# STM32WBA55 register map
File version: 1.0
CPU: CM33 r0p1, little endian, MPU, FPU, 4 interrupt priority bits
Registers are 32-bit, read-write, reset 0x0 unless marked. A register's access mark holds for its fields unless they carry their own. Offsets are from the block's base; [hi:lo] are bit positions; {n}, {i} and the like mark numbered series; 'fields as' and 'values as' point back to an identical list.

## GPDMA — General purpose direct memory access controller
Base 0x40020000
Same registers: SEC_GPDMA 0x50020000
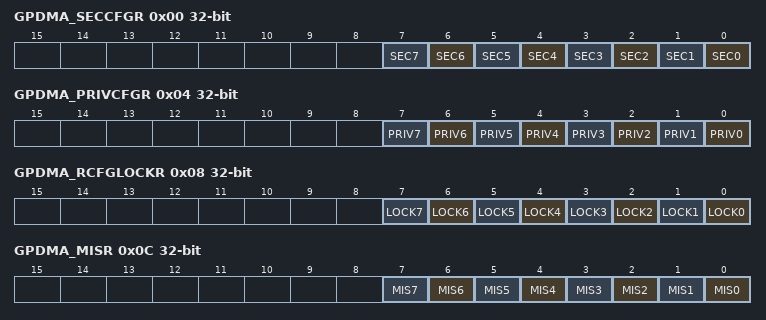
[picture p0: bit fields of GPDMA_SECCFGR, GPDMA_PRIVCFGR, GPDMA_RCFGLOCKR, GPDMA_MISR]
0x00 GPDMA_SECCFGR — GPDMA secure configuration register
  [all] fields
    0=non-secure; 1=secure
  [n] SEC{n} (n=0..7) — secure state of channel x
0x04 GPDMA_PRIVCFGR — GPDMA privileged configuration register
  [all] fields
    0=unprivileged; 1=privileged
  [n] PRIV{n} (n=0..7) — privileged state of channel x
0x08 GPDMA_RCFGLOCKR — GPDMA configuration lock register
  [all] fields
    0=secure privilege configuration of the channel x is writable; 1=secure privilege configuration of the channel x is not writable
  [n] LOCK{n} (n=0..7) — lock the configuration of GPDMA_SECCFGR.SECx and GPDMA_PRIVCFGR.PRIVx, until a global GPDMA reset This bit is cleared after reset and, once set, it cannot be reset until a global GPDMA reset.
0x0C GPDMA_MISR ro — GPDMA non-secure masked interrupt status register
  [all] fields
    0=no interrupt occurred on channel x; 1=an interrupt occurred on channel x
  [n] MIS{n} (n=0..7) — masked interrupt status of channel x
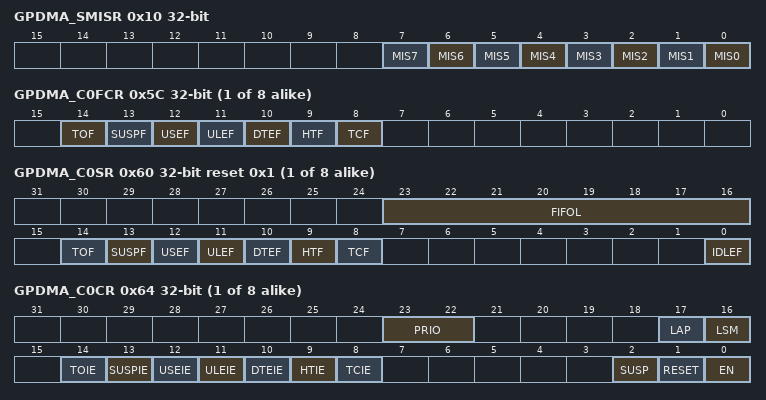
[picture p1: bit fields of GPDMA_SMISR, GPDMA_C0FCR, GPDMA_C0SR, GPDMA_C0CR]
0x10 GPDMA_SMISR ro — GPDMA secure masked interrupt status register
  [all] fields
    0=no interrupt occurred on the secure channel x; 1=an interrupt occurred on the secure channel x
  [n] MIS{n} (n=0..7) — masked interrupt status of the secure channel x
{0x50+0x80*i} GPDMA_C{i}LBAR (i=0..7) — GPDMA channel {i} linked-list base address register
  [31:16] LBA — linked-list base address of GPDMA channel x
{0x5C+0x80*i} GPDMA_C{i}FCR wo (i=0..7) — GPDMA channel {i} flag clear register
  [14] TOF — trigger overrun flag clear
    0=no effect; 1=corresponding TOF flag cleared
  [13] SUSPF — completed suspension flag clear
    0=no effect; 1=corresponding SUSPF flag cleared
  [12] USEF — user setting error flag clear
    0=no effect; 1=corresponding USEF flag cleared
  [11] ULEF — update link transfer error flag clear
    0=no effect; 1=corresponding ULEF flag cleared
  [10] DTEF — data transfer error flag clear
    0=no effect; 1=corresponding DTEF flag cleared
  [9] HTF — half transfer flag clear
    0=no effect; 1=corresponding HTF flag cleared
  [8] TCF — transfer complete flag clear
    0=no effect; 1=corresponding TCF flag cleared
{0x60+0x80*i} GPDMA_C{i}SR ro reset 0x1 (i=0..7) — GPDMA channel {i} status register
  [23:16] FIFOL — monitored FIFO level Number of available write beats in the FIFO, in units of the programmed destination data width (see GPDMA_CxTR1.DDW_LOG2[1:0], in units of bytes, half-words, or words). Note: After having suspended an active transfer, the user may need to read FIFOL[7:0], additionally to GPDMA_CxBR1.BDNT[15:0] to know how many data have been transferred to the destination. Before reading, the user may wait for the transfer to be suspended (GPDMA_CxSR.SUSPF = 1).
  [14] TOF — trigger overrun flag
    0=no trigger overrun event; 1=a trigger overrun event occurred
  [13] SUSPF — completed suspension flag
    0=no completed suspension event; 1=a completed suspension event occurred
  [12] USEF — user setting error flag
    0=no user setting error event; 1=a user setting error event occurred
  [11] ULEF — update link transfer error flag
    0=no update link transfer error event; 1=a master bus error event occurred while updating a linked-list register from memory
  [10] DTEF — data transfer error flag
    0=no data transfer error event; 1=a master bus error event occurred on a data transfer
  [9] HTF — half transfer flag A half block transfer occurs when half of the bytes of the source block size (rounded up integer of GPDMA_CxBR1.BNDT[15:0]/2) has been transferred to the destination.
    0=no half transfer event; 1=a half transfer event occurred
  [8] TCF — transfer complete flag A transfer complete event is either a block transfer complete, or a LLI transfer complete including the upload of the next LLI if any, or the full linked-list completion, depending on the transfer complete event mode (GPDMA_CxTR2.TCEM[1:0]).
    0=no transfer complete event; 1=a transfer complete event occurred
  [0] IDLEF — idle flag This idle flag is deasserted by hardware when the channel is enabled (GPDMA_CxCR.EN = 1) with a valid channel configuration (no USEF to be immediately reported). This idle flag is asserted after hard reset or by hardware when the channel is back in idle state (in suspended or disabled state).
    0=channel not in idle state; 1=channel in idle state
{0x64+0x80*i} GPDMA_C{i}CR access per field (i=0..7) — GPDMA channel {i} control register
  [23:22] PRIO rw — priority level of the channel x GPDMA transfer versus others Note: This bit must be written when EN = 0. This bit is read-only when EN = 1.
    0=low priority, low weight; 1=low priority, mid weight; 2=low priority, high weight; 3=high priority
  [17] LAP rw — linked-list allocated port This bit is used to allocate the master port for the update of the GPDMA linked-list registers from the memory. Note: This bit must be written when EN=0. This bit is read-only when EN=1.
    0=port 0 (AHB) allocated; 1=port 1 (AHB) allocated
  [16] LSM rw — Link step mode First the (possible 1D/repeated) block transfer is executed as defined by the current internal register file until GPDMA_CxBR1.BNDT[15:0] = 0. Secondly the next linked-list data structure is conditionally uploaded from memory as defined by GPDMA_CxLLR. Then channel execution is completed. Note: This bit must be written when EN=0. This bit is read-only when EN=1.
    0=channel executed for the full linked-list and completed at the end of the last LLI (GPDMA_CxLLR = 0). The 16 low-significant bits of the link address are null (LA[15:0] = 0) and all the update bits are null (UT1 =UB1 = UT2 = USA = UDA = ULL = 0). Then GPDMA_CxBR1.BNDT[15:0] = 0.; 1=channel executed once for the current LLI
  [14] TOIE rw — trigger overrun interrupt enable
    0=interrupt disabled; 1=interrupt enabled
  [13] SUSPIE rw — completed suspension interrupt enable
    0=interrupt disabled; 1=interrupt enabled
  [12] USEIE rw — user setting error interrupt enable
    0=interrupt disabled; 1=interrupt enabled
  [11] ULEIE rw — update link transfer error interrupt enable
    0=interrupt disabled; 1=interrupt enabled
  [10] DTEIE rw — data transfer error interrupt enable
    0=interrupt disabled; 1=interrupt enabled
  [9] HTIE rw — half transfer complete interrupt enable
    0=interrupt disabled; 1=interrupt enabled
  [8] TCIE rw — transfer complete interrupt enable
    0=interrupt disabled; 1=interrupt enabled
  [2] SUSP rw — suspend Writing 1 into the field RESET (bit 1) causes the hardware to de-assert this bit, whatever is written into this bit 2. Else: Software must write 1 in order to suspend an active channel (channel with an ongoing GPDMA transfer over its master ports). The software must write 0 in order to resume a suspended channel, following the programming sequence detailed in Figure 43.
    0=write: resume channel, read: channel not suspended; 1=write: suspend channel, read: channel suspended
  [1] RESET wo — reset This bit is write only. Writing 0 has no impact. Writing 1 implies the reset of the following: the FIFO, the channel internal state, SUSP and EN bits (whatever is written receptively in bit 2 and bit 0). The reset is effective when the channel is in steady state, meaning one of the following: - active channel in suspended state (GPDMA_CxSR.SUSPF = 1 and GPDMA_CxSR.IDLEF = GPDMA_CxCR.EN = 1) - channel in disabled state (GPDMA_CxSR.IDLEF = 1 and GPDMA_CxCR.EN = 0). After writing a RESET, to continue using this channel, the user must explicitly reconfigure the channel including the hardware-modified configuration registers (GPDMA_CxBR1, GPDMA_CxSAR and GPDMA_CxDAR) before enabling again the channel (see the programming sequence in Figure 44).
    0=no channel reset; 1=channel reset
  [0] EN rw — enable Writing 1 into the field RESET (bit 1) causes the hardware to de-assert this bit, whatever is written into this bit 0. Else: this bit is deasserted by hardware when there is a transfer error (master bus error or user setting error) or when there is a channel transfer complete (channel ready to be configured, for example if LSM=1 at the end of a single execution of the LLI). Else, this bit can be asserted by software. Writing 0 into this EN bit is ignored.
    0=write: ignored, read: channel disabled; 1=write: enable channel, read: channel enabled
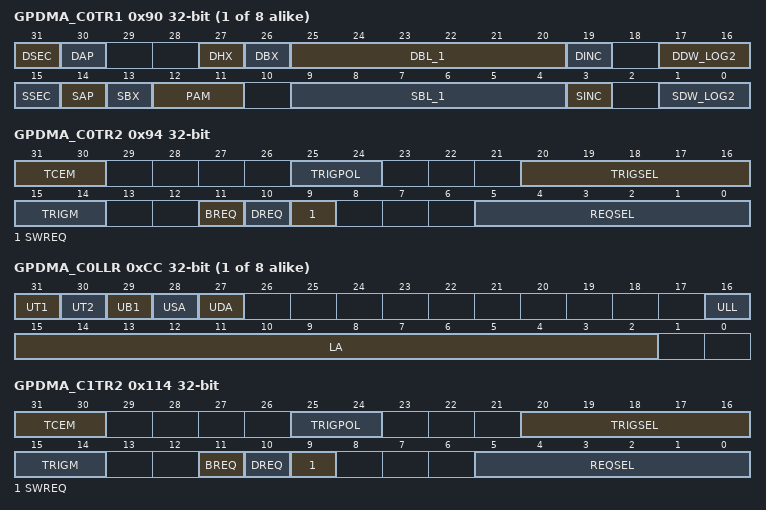
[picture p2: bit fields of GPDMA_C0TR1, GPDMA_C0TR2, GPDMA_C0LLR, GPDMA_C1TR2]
{0x90+0x80*i} GPDMA_C{i}TR1 (i=0..7) — GPDMA channel {i} transfer register 1
  [31] DSEC — security attribute of the GPDMA transfer to the destination If GPDMA_SECCFGR.SECx = 1 and the access is secure: This is a secure register bit. This bit can only be read by a secure software. This bit must be written by a secure software when GPDMA_SECCFGR.SECx = 1. A secure write is ignored when GPDMA_SECCFGR.SECx = 0. When GPDMA_SECCFGR.SECx is deasserted, this DSEC bit is also deasserted by hardware (on a secure reconfiguration of the channel as non-secure), and the GPDMA transfer to the destination is non-secure.
    0=GPDMA transfer non-secure; 1=GPDMA transfer secure
  [30] DAP — destination allocated port This bit is used to allocate the master port for the destination transfer Note: This bit must be written when EN = 0. This bit is read-only when EN = 1.
    0=port 0 (AHB) allocated; 1=port 1 (AHB) allocated
  [27] DHX — destination half-word exchange If the destination data size is shorter than a word, this bit is ignored. If the destination data size is a word:
    0=no halfword-based exchanged within word; 1=the two consecutive (post PAM) half-words are exchanged in each destination word
  [26] DBX — destination byte exchange If the destination data size is a byte, this bit is ignored. If the destination data size is not a byte:
    0=no byte-based exchange within half-word; 1=the two consecutive (post PAM) bytes are exchanged in each destination half-word
  [25:20] DBL_1 — destination burst length minus 1, between 0 and 63 The burst length unit is one data named beat within a burst. If DBL_1[5:0] =0 , the burst can be named as single. Each data/beat has a width defined by the destination data width DDW_LOG2[1:0]. Note: If a burst transfer crossed a 1-Kbyte address boundary on a AHB transfer, the GPDMA modifies and shortens the programmed burst into singles or bursts of lower length, to be compliant with the AHB protocol. Note: If a burst transfer is of length greater than the FIFO size of the channel x, the GPDMA modifies and shortens the programmed burst into singles or bursts of lower length, to be compliant with the FIFO size. Transfer performance is lower, with GPDMA re-arbitration between effective and lower singles/bursts, but the data integrity is guaranteed.
  [19] DINC — destination incrementing burst The destination address, pointed by GPDMA_CxDAR, is kept constant after a burst beat/single transfer, or is incremented by the offset value corresponding to a contiguous data after a burst beat/single transfer.
    0=fixed burst; 1=contiguously incremented burst
  [17:16] DDW_LOG2 — binary logarithm of the destination data width of a burst, in bytes Setting a 8-byte data width causes a user setting error to be reported and none transfer is issued. Note: A destination burst transfer must have an aligned address with its data width (start address GPDMA_CxDAR[2:0] versus DDW_LOG2[1:0]). Otherwise a user setting error is reported and no transfer is issued.
    0=byte; 1=half-word (2 bytes); 2=word (4 bytes); 3=user setting error reported and no transfer issued
  [15] SSEC — security attribute of the GPDMA transfer from the source If GPDMA_SECCFGR.SECx = 1 and the access is secure: This is a secure register bit. This bit can only be read by a secure software. This bit must be written by a secure software when GPDMA_SECCFGR.SECx =1 . A secure write is ignored when GPDMA_SECCFGR.SECx = 0. When GPDMA_SECCFGR.SECx is deasserted, this SSEC bit is also deasserted by hardware (on a secure reconfiguration of the channel as non-secure), and the GPDMA transfer from the source is non-secure.
    0=GPDMA transfer non-secure; 1=GPDMA transfer secure
  [14] SAP — source allocated port This bit is used to allocate the master port for the source transfer Note: This bit must be written when EN = 0. This bit is read-only when EN = 1.
    0=port 0 (AHB) allocated; 1=port 1 (AHB) allocated
  [13] SBX — source byte exchange within the unaligned half-word of each source word If the source data width is shorter than a word, this bit is ignored. If the source data width is a word:
    0=no byte-based exchange within the unaligned half-word of each source word; 1=the two consecutive bytes within the unaligned half-word of each source word are exchanged
  [12:11] PAM — padding/alignment mode If DDW_LOG2[1:0] = SDW_LOG2[1:0]: if the data width of a burst destination transfer is equal to the data width of a burst source transfer, these bits are ignored. Else, in the following enumerated values, the condition PAM_1 is when destination data width is higher that source data width, and the condition PAM_2 is when destination data width is higher than source data width. 1x: successive source data are FIFO queued and packed at the destination data width, in a left (LSB) to right (MSB) order (named little endian), before a destination transfer Note: 1x: source data is FIFO queued and unpacked at the destination data width, to be transferred in a left (LSB) to right (MSB) order (named little endian) to the destination
    0=B_0x0_PAM_1 (source data is transferred as right aligned, padded with 0s up to the destination data width); 1=B_0x1_PAM_1 (source data is transferred as right aligned, sign extended up to the destination data width)
  [9:4] SBL_1 — source burst length minus 1, between 0 and 63 The burst length unit is one data named beat within a burst. If SBL_1[5:0] =0 , the burst can be named as single. Each data/beat has a width defined by the destination data width SDW_LOG2[1:0]. Note: If a burst transfer crossed a 1-Kbyte address boundary on a AHB transfer, the GPDMA modifies and shortens the programmed burst into singles or bursts of lower length, to be compliant with the AHB protocol. Note: If a burst transfer is of length greater than the FIFO size of the channel x, the GPDMA modifies and shortens the programmed burst into singles or bursts of lower length, to be compliant with the FIFO size. Transfer performance is lower, with GPDMA re-arbitration between effective and lower singles/bursts, but the data integrity is guaranteed.
  [3] SINC — source incrementing burst The source address, pointed by GPDMA_CxSAR, is kept constant after a burst beat/single transfer or is incremented by the offset value corresponding to a contiguous data after a burst beat/single transfer.
    0=fixed burst; 1=contiguously incremented burst
  [1:0] SDW_LOG2 — binary logarithm of the source data width of a burst in bytes Setting a 8-byte data width causes a user setting error to be reported and no transfer is issued. A source block size must be a multiple of the source data width (GPDMA_CxBR1.BNDT[2:0] versus SDW_LOG2[1:0]). Otherwise, a user setting error is reported and no transfer is issued. Note: A source burst transfer must have an aligned address with its data width (start address GPDMA_CxSAR[2:0] versus SDW_LOG2[1:0]). Otherwise, a user setting error is reported and none transfer is issued.
    values as DDW_LOG2
0x94 GPDMA_C0TR2 — GPDMA channel 0 transfer register 2
  [31:30] TCEM — transfer complete event mode These bits define the transfer granularity for the transfer complete and half transfer complete events generation. Note: If the initial LLIsub0 /subdata transfer is null/void (directly programmed by the internal register file with GPDMA_CxBR1.BNDT[15:0] = 0), then neither the complete transfer event nor the half transfer event is generated. Note: If the initial LLIsub0 /subdata transfer is null/void (directly programmed by the internal register file with GPDMA_CxBR1.BNDT[15:0] = 0), then neither the complete transfer event nor the half transfer event is generated. Note: If the initial LLIsub0 /subdata transfer is null/void (i.e. directly programmed by the internal register file with GPDMA_CxBR1.BNDT[15:0] =0 ), then the half transfer event is not generated, and the transfer complete event is generated when is completed the loading of the LLIsub1/sub.
    0=at block level (when GPDMA_CxBR1.BNDT[15:0] = 0): the complete (and the half) transfer event is generated at the (respectively half of the) end of a block; 1=channel x (0 to 7, same as 00; 2=at LLI level: the complete transfer event is generated at the end of the LLI transfer, including the update of the LLI if any. The half transfer event is generated at the half of the LLI data transfer.; 3=at channel level: the complete transfer event is generated at the end of the last LLI transfer. The half transfer event is generated at the half of the data transfer of the last LLI. The last LLI updates the link address GPDMA_CxLLR.LA[15:2] to zero and clears all the GPDMA_CxLLR update bits (UT1, UT2, UB1, USA, UDA and ULL). If the channel transfer is continuous/infinite, no event is generated.
  [25:24] TRIGPOL — trigger event polarity These bits define the polarity of the selected trigger event input defined by TRIGSEL[4:0].
    0=no trigger (masked trigger event); 1=trigger on the rising edge; 2=trigger on the falling edge; 3=same as 00
  [20:16] TRIGSEL — trigger event input selection These bits select the trigger event input of the GPDMA transfer (as per Section 16.3.5), with an active trigger event if TRIGPOL[1:0] different 00.
  [15:14] TRIGM — trigger mode These bits define the transfer granularity for its conditioning by the trigger.
    0=at block level: the first burst read of each block transfer is conditioned by one hit trigger ; 1=channel x = 0 to 7, same as 0010: at link level: a LLI link transfer is conditioned by one hit trigger. The LLI data transfer (if any) is not conditioned.; 3=at programmed burst level: If SWREQ = 1, each programmed burst read is conditioned by one hit trigger. If SWREQ = 0, each programmed burst that is requested by the selected peripheral, is conditioned by one hit trigger.
  [11] BREQ — Block hardware request If the channel x is activated (GPDMA_CxCR.EN asserted) with SWREQ = 1 (software request for a memory-to-memory transfer), this bit is ignored. Else:
    0=the selected hardware request is driven by a peripheral with a hardware request/acknowledge protocol at a burst level; 1=the selected hardware request is driven by a peripheral with a hardware request/acknowledge protocol at a block level (see Section 16.3.3)
  [10] DREQ — destination hardware request This bit is ignored if channel x is activated (GPDMA_CxCR.EN asserted) with SWREQ = 1 (software request for a memory-to-memory transfer). Else:
    0=selected hardware request driven by a source peripheral (request signal taken into account by the GPDMA transfer scheduler over the source/read port); 1=selected hardware request driven by a destination peripheral (request signal taken into account by the GPDMA transfer scheduler over the destination/write port)
  [9] SWREQ — software request This bit is internally taken into account when GPDMA_CxCR.EN is asserted.
    0=no software request. The selected hardware request REQSEL[5:0] is taken into account.; 1=software request for a memory-to-memory transfer. The default selected hardware request as per REQSEL[5:0] is ignored.
  [5:0] REQSEL — GPDMA hardware request selection These bits are ignored if channel x is activated (GPDMA_CxCR.EN asserted) with SWREQ = 1 (software request for a memory-to-memory transfer). Else, the selected hardware request is internally taken into account as per Section 16.3.3. The user must not assign a same input hardware request (same REQSEL[5:0] value) to different active GPDMA channels (GPDMA_CxCR.EN = 1 and GPDMA_CxTR2.SWREQ = 0 for these channels). GPDMA is not intended to hardware support the case of simultaneous enabled channels incorrectly configured with a same hardware peripheral request signal, and there is no user setting error reporting.
{0x98+0x80*i} GPDMA_C{i}BR1 (i=0..7) — GPDMA channel {i} block register 1
  [15:0] BNDT — block number of data bytes to transfer from the source Block size transferred from the source. When the channel is enabled, this field becomes read-only and is decremented, indicating the remaining number of data items in the current source block to be transferred. BNDT[15:0] is programmed in number of bytes, maximum source block size is 64 Kbytes -1. Once the last data transfer is completed (BNDT[15:0] = 0): - if GPDMA_CxLLR.UB1 = 1, this field is updated by the LLI in the memory. - if GPDMA_CxLLR.UB1 = 0 and if there is at least one non null Uxx update bit, this field is internally restored to the programmed value. - if all GPDMA_CxLLR.Uxx = 0 and if GPDMA_CxLLR.LA[15:0] = 0, this field is internally restored to the programmed value (infinite/continuous last LLI). - if GPDMA_CxLLR = 0, this field is kept as zero following the last LLI data transfer. Note: A non-null source block size must be a multiple of the source data width (BNDT[2:0] versus GPDMA_CxTR1.SDW_LOG2[1:0]). Else a user setting error is reported and no transfer is issued. Note: When configured in packing mode (GPDMA_CxTR1.PAM[1] = 1 and destination data width different from source data width), a non-null source block size must be a multiple of the destination data width (BNDT[2:0] versus GPDMA_CxTR1.DDW_LOG2[1:0]). Else a user setting error is reported and no transfer is issued.
{0x9C+0x80*i} GPDMA_C{i}SAR (i=0..7) — GPDMA channel {i} source address register
  [31:0] SA — source address This field is the pointer to the address from which the next data is read. During the channel activity, depending on the source addressing mode (GPDMA_CxTR1.SINC), this field is kept fixed or incremented by the data width (GPDMA_CxTR1.SDW_LOG2[1:0]) after each burst source data, reflecting the next address from which data is read. During the channel activity, this address is updated after each completed source burst, consequently to: the programmed source burst; either in fixed addressing mode or in contiguous-data incremented mode. If contiguously incremented (GPDMA_CxTR1.SINC = 1), then the additional address offset value is the programmed burst size, as defined by GPDMA_CxTR1.SBL_1[5:0] and GPDMA_CxTR1.SDW_LOG2[21:0] the additional source incremented/decremented offset value as programmed by GPDMA_CxBR1.SDEC In linked-list mode, after a LLI data transfer is completed, this register is automatically updated by GPDMA from the memory, provided the LLI is set with GPDMA_CxLLR.USA = 1. Note: A source address must be aligned with the programmed data width of a source burst (SA[2:0] versus GPDMA_CxTR1.SDW_LOG2[1:0]). Else, a user setting error is reported and no transfer is issued.
{0xA0+0x80*i} GPDMA_C{i}DAR (i=0..7) — GPDMA channel {i} destination address register
  [31:0] DA — destination address This field is the pointer to the address from which the next data is written. During the channel activity, depending on the destination addressing mode (GPDMA_CxTR1.DINC), this field is kept fixed or incremented by the data width (GPDMA_CxTR1.DDW_LOG2[21:0]) after each burst destination data, reflecting the next address from which data is written. During the channel activity, this address is updated after each completed destination burst, consequently to: the programmed destination burst; either in fixed addressing mode or in contiguous-data incremented mode. If contiguously incremented (GPDMA_CxTR1.DINC = 1), then the additional address offset value is the programmed burst size, as defined by GPDMA_CxTR1.DBL_1[5:0] and GPDMA_CxTR1.DDW_LOG2[1:0] the additional destination incremented/decremented offset value as programmed by GPDMA_CxBR1.DDEC. In linked-list mode, after a LLI data transfer is completed, this register is automatically updated by the GPDMA from the memory, provided the LLI is set with GPDMA_CxLLR.UDA = 1. Note: A destination address must be aligned with the programmed data width of a destination burst (DA[2:0] versus GPDMA_CxTR1.DDW_LOG2[1:0]). Else, a user setting error is reported and no transfer is issued.
{0xCC+0x80*i} GPDMA_C{i}LLR (i=0..7) — GPDMA channel {i} linked-list address register
  [31] UT1 — Update GPDMA_CxTR1 from memory This bit controls the update of GPDMA_CxTR1 from the memory during the link transfer.
    0=no GPDMA_CxTR1 update; 1=GPDMA_CxTR1 update
  [30] UT2 — Update GPDMA_CxTR2 from memory This bit controls the update of GPDMA_CxTR2 from the memory during the link transfer.
    0=no GPDMA_CxTR2 update; 1=GPDMA_CxTR2 update
  [29] UB1 — Update GPDMA_CxBR1 from memory This bit controls the update of GPDMA_CxBR1 from the memory during the link transfer. If UB1 = 0 and if GPDMA_CxLLR different 0, the linked-list is not completed. GPDMA_CxBR1.BNDT[15:0] is then restored to the programmed value after data transfer is completed and before the link transfer.
    0=no GPDMA_CxBR1 update from memory (GPDMA_CxBR1.BNDT[15:0] restored if any link transfer); 1=GPDMA_CxBR1 update
  [28] USA — update GPDMA_CxSAR from memory This bit controls the update of GPDMA_CxSAR from the memory during the link transfer.
    0=no GPDMA_CxSAR update; 1=GPDMA_CxSAR update
  [27] UDA — Update GPDMA_CxDAR register from memory This bit is used to control the update of GPDMA_CxDAR from the memory during the link transfer.
    0=no GPDMA_CxDAR update; 1=GPDMA_CxDAR update
  [16] ULL — Update GPDMA_CxLLR register from memory This bit is used to control the update of GPDMA_CxLLR from the memory during the link transfer.
    0=no GPDMA_CxLLR update; 1=GPDMA_CxLLR update
  [15:2] LA — pointer (16-bit low-significant address) to the next linked-list data structure If UT1 = UT2 = UB1 = USA = UDA = ULL = 0 and if LA[15:20] = 0, the current LLI is the last one. The channel transfer is completed without any update of the linked-list GPDMA register file. Else, this field is the pointer to the memory address offset from which the next linked-list data structure is automatically fetched from, once the data transfer is completed, in order to conditionally update the linked-list GPDMA internal register file (GPDMA_CxCTR1, GPDMA_CxTR2, GPDMA_CxBR1, GPDMA_CxSAR, GPDMA_CxDAR and GPDMA_CxLLR). Note: The user must program the pointer to be 32-bit aligned. The two low-significant bits are write ignored.
0x114 GPDMA_C1TR2 — GPDMA channel 1 transfer register 2
  [31:30] TCEM — transfer complete event mode These bits define the transfer granularity for the transfer complete and half transfer complete events generation. Note: If the initial LLIsub0 /subdata transfer is null/void (directly programmed by the internal register file with GPDMA_CxBR1.BNDT[15:0] = 0), then neither the complete transfer event nor the half transfer event is generated. Note: If the initial LLIsub0 /subdata transfer is null/void (directly programmed by the internal register file with GPDMA_CxBR1.BNDT[15:0] = 0), then neither the complete transfer event nor the half transfer event is generated. Note: If the initial LLIsub0 /subdata transfer is null/void (i.e. directly programmed by the internal register file with GPDMA_CxBR1.BNDT[15:0] =0 ), then the half transfer event is not generated, and the transfer complete event is generated when is completed the loading of the LLIsub1/sub.
    values as GPDMA_C0TR2.TCEM
  [25:24] TRIGPOL — trigger event polarity These bits define the polarity of the selected trigger event input defined by TRIGSEL[4:0].
    values as GPDMA_C0TR2.TRIGPOL
  [20:16] TRIGSEL — trigger event input selection These bits select the trigger event input of the GPDMA transfer (as per Section 16.3.5), with an active trigger event if TRIGPOL[1:0] different 00.
  [15:14] TRIGM — trigger mode These bits define the transfer granularity for its conditioning by the trigger. If the channel x is enabled (GPDMA_CxCR.EN asserted) with TRIGPOL[1:0] = 00 or 11, these TRIGM[1:0] bits are ignored.
    values as GPDMA_C0TR2.TRIGM
  [11] BREQ — Block hardware request If the channel x is activated (GPDMA_CxCR.EN asserted) with SWREQ = 1 (software request for a memory-to-memory transfer), this bit is ignored. Else:
    values as GPDMA_C0TR2.BREQ
  [10] DREQ — destination hardware request This bit is ignored if channel x is activated (GPDMA_CxCR.EN asserted) with SWREQ = 1 (software request for a memory-to-memory transfer). Else:
    values as GPDMA_C0TR2.DREQ
  [9] SWREQ — software request This bit is internally taken into account when GPDMA_CxCR.EN is asserted.
    values as GPDMA_C0TR2.SWREQ
  [5:0] REQSEL — GPDMA hardware request selection These bits are ignored if channel x is activated (GPDMA_CxCR.EN asserted) with SWREQ = 1 (software request for a memory-to-memory transfer). Else, the selected hardware request is internally taken into account as per Section 16.3.3. The user must not assign a same input hardware request (same REQSEL[5:0] value) to different active GPDMA channels (GPDMA_CxCR.EN = 1 and GPDMA_CxTR2.SWREQ = 0 for these channels). GPDMA is not intended to hardware support the case of simultaneous enabled channels incorrectly configured with a same hardware peripheral request signal, and there is no user setting error reporting.
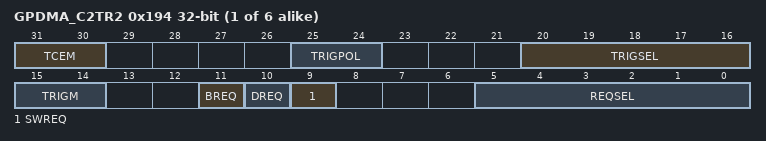
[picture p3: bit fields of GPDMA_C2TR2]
{0x94+0x80*i} GPDMA_C{i}TR2 (i=2..7) — GPDMA channel {i} transfer register 2
  fields as GPDMA_C0TR2
